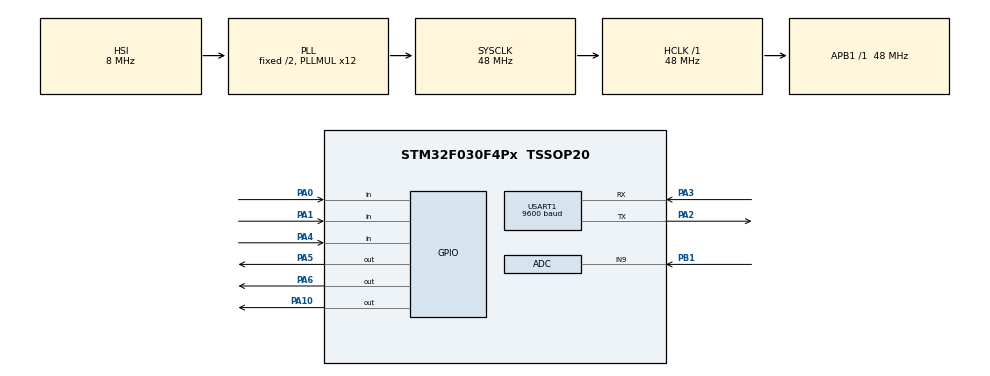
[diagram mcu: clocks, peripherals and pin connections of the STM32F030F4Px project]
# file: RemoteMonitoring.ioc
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ADC.ContinuousConvMode=ENABLE
ADC.DMAContinuousRequests=ENABLE
ADC.SamplingTime=ADC_SAMPLETIME_239CYCLES_5
Dma.ADC.0.Direction=DMA_PERIPH_TO_MEMORY
Dma.ADC.0.Instance=DMA1_Channel1
Dma.ADC.0.MemDataAlignment=DMA_MDATAALIGN_HALFWORD
Dma.ADC.0.MemInc=DMA_MINC_ENABLE
Dma.ADC.0.Mode=DMA_CIRCULAR
Dma.ADC.0.PeriphDataAlignment=DMA_PDATAALIGN_HALFWORD
Dma.ADC.0.PeriphInc=DMA_PINC_DISABLE
Dma.ADC.0.Priority=DMA_PRIORITY_LOW
Dma.Request0=ADC
Mcu.Family=STM32F0
Mcu.Name=STM32F030F4Px
Mcu.Package=TSSOP20
NVIC.DMA1_Channel1_IRQn=true\:0\:0\:false\:false\:true\:false\:true
NVIC.USART1_IRQn=true\:0\:0\:false\:false\:true\:true\:true
PA0.Signal=GPIO_Input
PA1.Signal=GPIO_Input
PA10.Signal=GPIO_Output
PA13.Mode=Serial_Wire
PA13.Signal=SYS_SWDIO
PA14.Mode=Serial_Wire
PA14.Signal=SYS_SWCLK
PA2.Mode=Asynchronous
PA2.Signal=USART1_TX
PA3.Mode=Asynchronous
PA3.Signal=USART1_RX
PA4.Signal=GPIO_Input
PA5.Signal=GPIO_Output
PA6.Signal=GPIO_Output
PB1.Mode=IN9
PB1.Signal=ADC_IN9
ProjectManager.HeapSize=0x200
ProjectManager.StackSize=0x400
ProjectManager.TargetToolchain=MDK-ARM V5
RCC.AHBFreq_Value=48000000
RCC.APB1Freq_Value=48000000
RCC.APB1TimFreq_Value=48000000
RCC.HCLKFreq_Value=48000000
RCC.PLLMUL=RCC_PLL_MUL12
RCC.SYSCLKFreq_VALUE=48000000
RCC.SYSCLKSource=RCC_SYSCLKSOURCE_PLLCLK
USART1.BaudRate=9600
USART1.VirtualMode-Asynchronous=VM_ASYNC
board=custom

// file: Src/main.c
/* USER CODE BEGIN Header */
/**
  ******************************************************************************
  * @file           : main.c
  * @brief          : Main program body
  ******************************************************************************
  * @attention
  *
  * <h2><center>&copy; Copyright (c) 2019 STMicroelectronics.
  * All rights reserved.</center></h2>
  *
  * This software component is licensed by ST under BSD 3-Clause license,
  * the "License"; You may not use this file except in compliance with the
  * License. You may obtain a copy of the License at:
  *                        opensource.org/licenses/BSD-3-Clause
  *
  ******************************************************************************
  */
/* USER CODE END Header */

#include "main.h"

/* USER CODE BEGIN PD */
#define Relay1_On HAL_GPIO_WritePin(GPIOA, GPIO_PIN_10, GPIO_PIN_SET)
#define Relay1_Off HAL_GPIO_WritePin(GPIOA, GPIO_PIN_10, GPIO_PIN_RESET)

#define Relay2_On HAL_GPIO_WritePin(GPIOA, GPIO_PIN_6, GPIO_PIN_SET)
#define Relay2_Off HAL_GPIO_WritePin(GPIOA, GPIO_PIN_6, GPIO_PIN_RESET)

#define Relay3_On HAL_GPIO_WritePin(GPIOA, GPIO_PIN_5, GPIO_PIN_SET)
#define Relay3_Off HAL_GPIO_WritePin(GPIOA, GPIO_PIN_5, GPIO_PIN_RESET)

/* USER CODE END PD */

ADC_HandleTypeDef hadc;
DMA_HandleTypeDef hdma_adc;

UART_HandleTypeDef huart1;

/* USER CODE BEGIN PV */
uint16_t temperature, ADC_buffer[1];
uint8_t rx;
/* USER CODE END PV */

void SystemClock_Config(void);
static void MX_GPIO_Init(void);
static void MX_DMA_Init(void);
static void MX_ADC_Init(void);
static void MX_USART1_UART_Init(void);
/* USER CODE BEGIN PFP */
void HAL_UART_RxCpltCallback(UART_HandleTypeDef *huart)
{
	HAL_UART_Receive_IT(&huart1,&rx,1);
	//HAL_GPIO_TogglePin(GPIOC,GPIO_PIN_13);
	HAL_UART_Transmit(&huart1,&rx,1,100);
}
/* USER CODE END PFP */

int main(void)
{

  /* MCU Configuration--------------------------------------------------------*/

  /* Reset of all peripherals, Initializes the Flash interface and the Systick. */
  HAL_Init();

  /* Configure the system clock */
  SystemClock_Config();

  /* Initialize all configured peripherals */
  MX_GPIO_Init();
  MX_DMA_Init();
  MX_ADC_Init();
  MX_USART1_UART_Init();
  /* USER CODE BEGIN 2 */
  HAL_ADC_Start_DMA(&hadc,(uint32_t *)ADC_buffer,1);
	HAL_UART_Receive_IT(&huart1, &rx, 1);
  /* USER CODE END 2 */

  /* Infinite loop */
  /* USER CODE BEGIN WHILE */
  while (1)
  {
		temperature = (ADC_buffer[0]*3.3)/4096;

    /* USER CODE END WHILE */

  }
}

void SystemClock_Config(void)
{
  RCC_OscInitTypeDef RCC_OscInitStruct = {0};
  RCC_ClkInitTypeDef RCC_ClkInitStruct = {0};
  RCC_PeriphCLKInitTypeDef PeriphClkInit = {0};

  /** Initializes the CPU, AHB and APB busses clocks
  */
  RCC_OscInitStruct.OscillatorType = RCC_OSCILLATORTYPE_HSI|RCC_OSCILLATORTYPE_HSI14;
  RCC_OscInitStruct.HSIState = RCC_HSI_ON;
  RCC_OscInitStruct.HSI14State = RCC_HSI14_ON;
  RCC_OscInitStruct.HSICalibrationValue = RCC_HSICALIBRATION_DEFAULT;
  RCC_OscInitStruct.HSI14CalibrationValue = 16;
  RCC_OscInitStruct.PLL.PLLState = RCC_PLL_ON;
  RCC_OscInitStruct.PLL.PLLSource = RCC_PLLSOURCE_HSI;
  RCC_OscInitStruct.PLL.PLLMUL = RCC_PLL_MUL12;
  RCC_OscInitStruct.PLL.PREDIV = RCC_PREDIV_DIV1;
  if (HAL_RCC_OscConfig(&RCC_OscInitStruct) != HAL_OK)
  {
    Error_Handler();
  }
  /** Initializes the CPU, AHB and APB busses clocks
  */
  RCC_ClkInitStruct.ClockType = RCC_CLOCKTYPE_HCLK|RCC_CLOCKTYPE_SYSCLK
                              |RCC_CLOCKTYPE_PCLK1;
  RCC_ClkInitStruct.SYSCLKSource = RCC_SYSCLKSOURCE_PLLCLK;
  RCC_ClkInitStruct.AHBCLKDivider = RCC_SYSCLK_DIV1;
  RCC_ClkInitStruct.APB1CLKDivider = RCC_HCLK_DIV1;

  if (HAL_RCC_ClockConfig(&RCC_ClkInitStruct, FLASH_LATENCY_1) != HAL_OK)
  {
    Error_Handler();
  }
  PeriphClkInit.PeriphClockSelection = RCC_PERIPHCLK_USART1;
  PeriphClkInit.Usart1ClockSelection = RCC_USART1CLKSOURCE_PCLK1;
  if (HAL_RCCEx_PeriphCLKConfig(&PeriphClkInit) != HAL_OK)
  {
    Error_Handler();
  }
}

static void MX_ADC_Init(void)
{

  ADC_ChannelConfTypeDef sConfig = {0};

  /** Configure the global features of the ADC (Clock, Resolution, Data Alignment and number of conversion)
  */
  hadc.Instance = ADC1;
  hadc.Init.ClockPrescaler = ADC_CLOCK_ASYNC_DIV1;
  hadc.Init.Resolution = ADC_RESOLUTION_12B;
  hadc.Init.DataAlign = ADC_DATAALIGN_RIGHT;
  hadc.Init.ScanConvMode = ADC_SCAN_DIRECTION_FORWARD;
  hadc.Init.EOCSelection = ADC_EOC_SINGLE_CONV;
  hadc.Init.LowPowerAutoWait = DISABLE;
  hadc.Init.LowPowerAutoPowerOff = DISABLE;
  hadc.Init.ContinuousConvMode = ENABLE;
  hadc.Init.DiscontinuousConvMode = DISABLE;
  hadc.Init.ExternalTrigConv = ADC_SOFTWARE_START;
  hadc.Init.ExternalTrigConvEdge = ADC_EXTERNALTRIGCONVEDGE_NONE;
  hadc.Init.DMAContinuousRequests = ENABLE;
  hadc.Init.Overrun = ADC_OVR_DATA_PRESERVED;
  if (HAL_ADC_Init(&hadc) != HAL_OK)
  {
    Error_Handler();
  }
  /** Configure for the selected ADC regular channel to be converted.
  */
  sConfig.Channel = ADC_CHANNEL_9;
  sConfig.Rank = ADC_RANK_CHANNEL_NUMBER;
  sConfig.SamplingTime = ADC_SAMPLETIME_239CYCLES_5;
  if (HAL_ADC_ConfigChannel(&hadc, &sConfig) != HAL_OK)
  {
    Error_Handler();
  }

}

static void MX_USART1_UART_Init(void)
{

  huart1.Instance = USART1;
  huart1.Init.BaudRate = 9600;
  huart1.Init.WordLength = UART_WORDLENGTH_8B;
  huart1.Init.StopBits = UART_STOPBITS_1;
  huart1.Init.Parity = UART_PARITY_NONE;
  huart1.Init.Mode = UART_MODE_TX_RX;
  huart1.Init.HwFlowCtl = UART_HWCONTROL_NONE;
  huart1.Init.OverSampling = UART_OVERSAMPLING_16;
  huart1.Init.OneBitSampling = UART_ONE_BIT_SAMPLE_DISABLE;
  huart1.AdvancedInit.AdvFeatureInit = UART_ADVFEATURE_NO_INIT;
  if (HAL_UART_Init(&huart1) != HAL_OK)
  {
    Error_Handler();
  }

}

static void MX_DMA_Init(void)
{

  /* DMA controller clock enable */
  __HAL_RCC_DMA1_CLK_ENABLE();

  /* DMA interrupt init */
  /* DMA1_Channel1_IRQn interrupt configuration */
  HAL_NVIC_SetPriority(DMA1_Channel1_IRQn, 0, 0);
  HAL_NVIC_EnableIRQ(DMA1_Channel1_IRQn);

}

static void MX_GPIO_Init(void)
{
  GPIO_InitTypeDef GPIO_InitStruct = {0};

  /* GPIO Ports Clock Enable */
  __HAL_RCC_GPIOA_CLK_ENABLE();
  __HAL_RCC_GPIOB_CLK_ENABLE();

  /*Configure GPIO pin Output Level */
  HAL_GPIO_WritePin(GPIOA, GPIO_PIN_5|GPIO_PIN_6|GPIO_PIN_10, GPIO_PIN_RESET);

  /*Configure GPIO pins : PA0 PA1 PA4 */
  GPIO_InitStruct.Pin = GPIO_PIN_0|GPIO_PIN_1|GPIO_PIN_4;
  GPIO_InitStruct.Mode = GPIO_MODE_INPUT;
  GPIO_InitStruct.Pull = GPIO_NOPULL;
  HAL_GPIO_Init(GPIOA, &GPIO_InitStruct);

  /*Configure GPIO pins : PA5 PA6 PA10 */
  GPIO_InitStruct.Pin = GPIO_PIN_5|GPIO_PIN_6|GPIO_PIN_10;
  GPIO_InitStruct.Mode = GPIO_MODE_OUTPUT_PP;
  GPIO_InitStruct.Pull = GPIO_NOPULL;
  GPIO_InitStruct.Speed = GPIO_SPEED_FREQ_LOW;
  HAL_GPIO_Init(GPIOA, &GPIO_InitStruct);

}

void Error_Handler(void)
{
}

/************************ (C) COPYRIGHT STMicroelectronics *****END OF FILE****/
